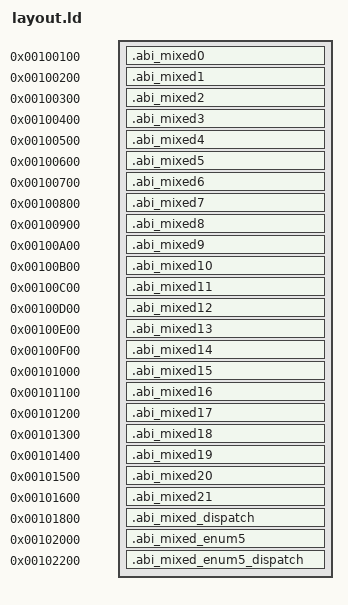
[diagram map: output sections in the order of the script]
SECTIONS {
  .abi_mixed0 0x100100 : { *(.abi_mixed0) }
  .abi_mixed1 0x100200 : { *(.abi_mixed1) }
  .abi_mixed2 0x100300 : { *(.abi_mixed2) }
  .abi_mixed3 0x100400 : { *(.abi_mixed3) }
  .abi_mixed4 0x100500 : { *(.abi_mixed4) }
  .abi_mixed5 0x100600 : { *(.abi_mixed5) }
  .abi_mixed6 0x100700 : { *(.abi_mixed6) }
  .abi_mixed7 0x100800 : { *(.abi_mixed7) }
  .abi_mixed8 0x100900 : { *(.abi_mixed8) }
  .abi_mixed9 0x100a00 : { *(.abi_mixed9) }
  .abi_mixed10 0x100b00 : { *(.abi_mixed10) }
  .abi_mixed11 0x100c00 : { *(.abi_mixed11) }
  .abi_mixed12 0x100d00 : { *(.abi_mixed12) }
  .abi_mixed13 0x100e00 : { *(.abi_mixed13) }
  .abi_mixed14 0x100f00 : { *(.abi_mixed14) }
  .abi_mixed15 0x101000 : { *(.abi_mixed15) }
  .abi_mixed16 0x101100 : { *(.abi_mixed16) }
  .abi_mixed17 0x101200 : { *(.abi_mixed17) }
  .abi_mixed18 0x101300 : { *(.abi_mixed18) }
  .abi_mixed19 0x101400 : { *(.abi_mixed19) }
  .abi_mixed20 0x101500 : { *(.abi_mixed20) }
  .abi_mixed21 0x101600 : { *(.abi_mixed21) }
  .abi_mixed_dispatch 0x101800 : { *(.abi_mixed_dispatch) }
  .abi_mixed_enum5 0x102000 : { *(.abi_mixed_enum5) }
  .abi_mixed_enum5_dispatch 0x102200 : { *(.abi_mixed_enum5_dispatch) }
} INSERT AFTER .text;
